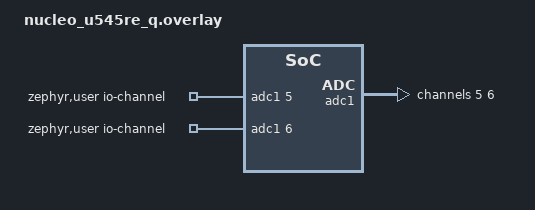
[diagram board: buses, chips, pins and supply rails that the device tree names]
/*
 * SPDX-License-Identifier: Apache-2.0
 *
 * Copyright (c) 2026 Smile
 */

/ {
	zephyr,user {
		/* adjust channel number according to pinmux in board.dts */
		io-channels = <&adc1 5>, <&adc1 6>;
	};
};

&adc1 {
	#address-cells = <1>;
	#size-cells = <0>;

	channel@5 {
		reg = <5>; /* Arduino A0 */
		zephyr,gain = "ADC_GAIN_1";
		zephyr,reference = "ADC_REF_INTERNAL";
		zephyr,acquisition-time = <ADC_ACQ_TIME_DEFAULT>;
		zephyr,resolution = <14>;
	};

	channel@6 {
		reg = <6>; /* Arduino A1 */
		zephyr,gain = "ADC_GAIN_1";
		zephyr,reference = "ADC_REF_INTERNAL";
		zephyr,acquisition-time = <ADC_ACQ_TIME_DEFAULT>;
		zephyr,resolution = <14>;
	};
};
